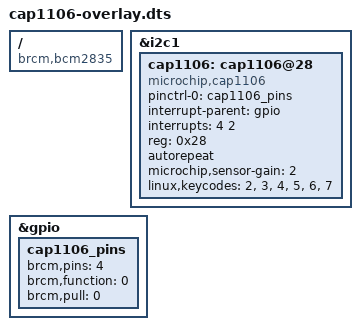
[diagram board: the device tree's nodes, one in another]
// Overlay for cap1106 from  Microchip Semiconductor
// add CONFIG_KEYBOARD_CAP11XX=y

/dts-v1/;
/plugin/;

/ {
        compatible = "brcm,bcm2835";
        fragment@0 {
                target = <&i2c1>;
                __overlay__{
                        status = "okay";
                        cap1106: cap1106@28 {
                                compatible = "microchip,cap1106";
                                pinctrl-0 = <&cap1106_pins>;
                                pinctrl-names = "default";
                                interrupt-parent = <&gpio>;
                                interrupts = <4 2>;
                                reg = <0x28>;
                                autorepeat;
                                microchip,sensor-gain = <2>;

                                linux,keycodes = <2>,           /* KEY_1 */
                                                <3>,            /* KEY_2 */
                                                <4>,            /* KEY_3 */
                                                <5>,            /* KEY_4 */
                                                <6>,            /* KEY_5 */
                                                <7>;            /* KEY_6 */

                                #address-cells = <1>;
                                #size-cells = <0>;
                                status = "okay";

                        };
                };
        };
        fragment@1 {
                target = <&gpio>;
                __overlay__ {
                        cap1106_pins: cap1106_pins {
                                brcm,pins = <4>;
                                brcm,function = <0>; /* in */
                                brcm,pull = <0>; /* none */
                        };
                };
        };

        __overrides__ {
                int_pin = <&cap1106>, "interrupts:0",
                          <&cap1106_pins>, "brcm,pins:0";
        };
};
